AUTOSAR XML (schema 4-0-3)
package /RcCar
  7 x sender receiver interface:
    IfVehicleInfo
      4 x data:
        angle: type=IDT_Angle
        speed: type=IDT_Speed
        pwm_angle: type=IDT_PWM
        pwm_speed: type=IDT_PWM
    IfWinker
      data state: type=IDT_Winker
    IfBuzzer
      data state: type=IDT_Buzzer
    IfLight
      4 x data, all with type=IDT_Light:
        head
        fog
        brake
        back
    IfDriving
      5 x data:
        angle: type=IDT_Angle
        speed: type=IDT_Speed
        steer: type=IDT_Adjust
        gain: type=IDT_Adjust
        brake: type=IDT_Brake
    IfBody
      5 x data, all with type=IDT_Light:
        head
        fog
        hazard
        winker_r
        winker_l
    IfDisplayMode
      6 x data:
        cycle: type=IDT_Cycle
        differ: type=IDT_Switch
        speed: type=IDT_Switch
        angle: type=IDT_Switch
        pwm_angle: type=IDT_PWM
        pwm_speed: type=IDT_PWM
  4 x client server interface:
    IfSteerAngle
      operation OpSetSteerAngle
        arg angle: type=IDT_Angle, direction=IN
    IfDriveSpeed
      operation OpSetDriveSpeed
        arg speed: type=IDT_Speed, direction=IN
    IfDisplayCommand
      operation OpGetDisplayCommand
        arg command: type=IDT_Disp, direction=OUT
    IfPS3Command
      operation OpGetIfPS3Command
        arg command: type=IDT_PS3, direction=OUT
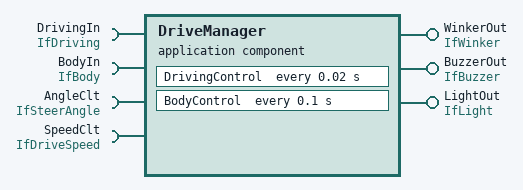
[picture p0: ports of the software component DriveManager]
  application sw component type DriveManager
    provide port WinkerOut: nonqueued-sender-com-spec{data-element=IfWinker/state, init-value=IDT_Winker:0}, provided-interface=IfWinker
    provide port BuzzerOut: nonqueued-sender-com-spec{data-element=IfBuzzer/state, init-value=IDT_Buzzer:0}, provided-interface=IfBuzzer
    provide port LightOut: provided-interface=IfLight
      provided-com-specs:
        data-element=back, init-value=IDT_Light:0
        data-element=IfLight/brake, init-value=IDT_Light:0
        data-element=IfLight/head, init-value=IDT_Light:0
        data-element=IfLight/fog, init-value=IDT_Light:0
    4 x require port:
      DrivingIn: required-interface=IfDriving
        required-com-specs:
          data-element=IfDriving/brake, enable-update=true, handle-never-received=true, init-value=IDT_Brake:1
          data-element=IfDriving/angle, enable-update=true, handle-never-received=true, init-value=IDT_Angle:0
          data-element=gain, enable-update=true, handle-never-received=true, init-value=IDT_Adjust:0
          data-element=IfDriving/speed, enable-update=true, handle-never-received=true, init-value=IDT_Speed:0
          data-element=steer, enable-update=true, handle-never-received=true, init-value=IDT_Adjust:0
      BodyIn: required-interface=IfBody
        required-com-specs:
          data-element=IfBody/fog, enable-update=true, handle-never-received=true, init-value=IDT_Light:0
          data-element=hazard, enable-update=true, handle-never-received=true, init-value=IDT_Light:0
          data-element=IfBody/head, enable-update=true, handle-never-received=true, init-value=IDT_Light:0
          data-element=winker_l, enable-update=true, handle-never-received=true, init-value=IDT_Light:0
          data-element=winker_r, enable-update=true, handle-never-received=true, init-value=IDT_Light:0
      AngleClt: required-interface=IfSteerAngle
      SpeedClt: required-interface=IfDriveSpeed
    behavior IB_DM: handle-termination-and-restart=NO-SUPPORT
      timing event DrivingControl_timingEvent: start-on-event=DrivingControl, period=0.02
      timing event BodyControl_timingEvent: start-on-event=BodyControl, period=0.1
      runnable DrivingControl
        data-receive-point-by-arguments:
          5 x access:
            dataReceivePoint_DrivingControl_DrivingIn_angle: accessed-variable=DrivingIn.angle
            dataReceivePoint_DrivingControl_DrivingIn_speed: accessed-variable=DrivingIn.speed
            dataReceivePoint_DrivingControl_DrivingIn_steer: accessed-variable=DrivingIn.steer
            dataReceivePoint_DrivingControl_DrivingIn_gain: accessed-variable=DrivingIn.gain
            dataReceivePoint_DrivingControl_DrivingIn_brake: accessed-variable=DrivingIn.brake
        sync call serverCallPoint_DrivingControl_AngleClt_OpSetSteerAngle: operation=AngleClt.OpSetSteerAngle, timeout=0.0
        sync call serverCallPoint_DrivingControl_SpeedClt_OpSetDriveSpeed: operation=SpeedClt.OpSetDriveSpeed, timeout=0.0
      runnable BodyControl
        data-receive-point-by-arguments:
          5 x access:
            dataReceivePoint_BodyControl_BodyIn_head: accessed-variable=BodyIn.head
            dataReceivePoint_BodyControl_BodyIn_fog: accessed-variable=BodyIn.fog
            dataReceivePoint_BodyControl_BodyIn_hazard: accessed-variable=BodyIn.hazard
            dataReceivePoint_BodyControl_BodyIn_winker_r: accessed-variable=BodyIn.winker_r
            dataReceivePoint_BodyControl_BodyIn_winker_l: accessed-variable=BodyIn.winker_l
        data-send-points:
          6 x access:
            dataSendPoint_BodyControl_WinkerOut_state: accessed-variable=WinkerOut.state
            dataSendPoint_BodyControl_BuzzerOut_state: accessed-variable=BuzzerOut.state
            dataSendPoint_BodyControl_LightOut_head: accessed-variable=LightOut.head
            dataSendPoint_BodyControl_LightOut_fog: accessed-variable=LightOut.fog
            dataSendPoint_BodyControl_LightOut_brake: accessed-variable=LightOut.brake
            dataSendPoint_BodyControl_LightOut_back: accessed-variable=LightOut.back
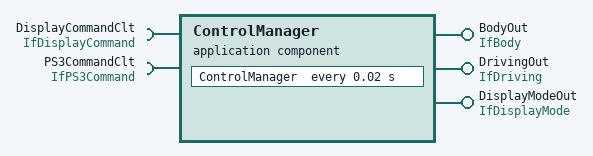
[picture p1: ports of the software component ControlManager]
  application sw component type ControlManager
    provide port BodyOut: provided-interface=IfBody
      provided-com-specs:
        data-element=IfBody/fog, init-value=IDT_Light:0
        data-element=hazard, init-value=IDT_Light:0
        data-element=IfBody/head, init-value=IDT_Light:0
        data-element=winker_l, init-value=IDT_Light:0
        data-element=winker_r, init-value=IDT_Light:0
    provide port DrivingOut: provided-interface=IfDriving
      provided-com-specs:
        data-element=IfDriving/brake, init-value=IDT_Brake:0
        data-element=IfDriving/angle, init-value=IDT_Angle:0
        data-element=gain, init-value=IDT_Adjust:0
        data-element=IfDriving/speed, init-value=IDT_Speed:0
        data-element=steer, init-value=IDT_Adjust:0
    provide port DisplayModeOut: provided-interface=IfDisplayMode
      provided-com-specs:
        data-element=IfDisplayMode/angle, init-value=IDT_Switch:0
        data-element=cycle, init-value=IDT_Cycle:0
        data-element=IfDisplayMode/speed, init-value=IDT_Switch:0
        data-element=differ, init-value=IDT_Switch:0
        data-element=IfDisplayMode/pwm_angle, init-value=IDT_PWM:0
        data-element=IfDisplayMode/pwm_speed, init-value=IDT_PWM:0
    require port DisplayCommandClt: required-interface=IfDisplayCommand
    require port PS3CommandClt: required-interface=IfPS3Command
    behavior IB_CM: handle-termination-and-restart=NO-SUPPORT
      timing event ControlManager_timingEvent: start-on-event=ControlManager, period=0.02
      runnable ControlManager
        data-send-points:
          16 x access:
            dataSendPoint_ControlManager_DrivingOut_angle: accessed-variable=DrivingOut.angle
            dataSendPoint_ControlManager_DrivingOut_speed: accessed-variable=DrivingOut.speed
            dataSendPoint_ControlManager_DrivingOut_steer: accessed-variable=DrivingOut.steer
            dataSendPoint_ControlManager_DrivingOut_gain: accessed-variable=DrivingOut.gain
            dataSendPoint_ControlManager_DrivingOut_brake: accessed-variable=DrivingOut.brake
            dataSendPoint_ControlManager_BodyOut_head: accessed-variable=BodyOut.head
            dataSendPoint_ControlManager_BodyOut_fog: accessed-variable=BodyOut.fog
            dataSendPoint_ControlManager_BodyOut_hazard: accessed-variable=BodyOut.hazard
            dataSendPoint_ControlManager_BodyOut_winker_r: accessed-variable=BodyOut.winker_r
            dataSendPoint_ControlManager_BodyOut_winker_l: accessed-variable=BodyOut.winker_l
            dataSendPoint_ControlManager_DisplayModeOut_cycle: accessed-variable=DisplayModeOut.cycle
            dataSendPoint_ControlManager_DisplayModeOut_differ: accessed-variable=DisplayModeOut.differ
            dataSendPoint_ControlManager_DisplayModeOut_speed: accessed-variable=DisplayModeOut.speed
            dataSendPoint_ControlManager_DisplayModeOut_angle: accessed-variable=DisplayModeOut.angle
            dataSendPoint_ControlManager_DisplayModeOut_pwm_angle: accessed-variable=DisplayModeOut.pwm_angle
            dataSendPoint_ControlManager_DisplayModeOut_pwm_speed: accessed-variable=DisplayModeOut.pwm_speed
        sync call serverCallPoint_ControlManager_DisplayCommandClt_OpGetDisplayCommand: operation=DisplayCommandClt.OpGetDisplayCommand, timeout=0.0
        sync call serverCallPoint_ControlManager_PS3CommandClt_OpGetIfPS3Command: operation=PS3CommandClt.OpGetIfPS3Command, timeout=0.0
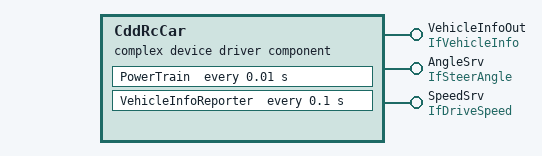
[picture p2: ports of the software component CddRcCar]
  complex device driver sw component type CddRcCar
    provide port VehicleInfoOut: provided-interface=IfVehicleInfo
      provided-com-specs:
        data-element=IfVehicleInfo/angle, init-value=IDT_Angle:0
        data-element=IfVehicleInfo/speed, init-value=IDT_Speed:0
        data-element=IfVehicleInfo/pwm_angle, init-value=IDT_PWM:0
        data-element=IfVehicleInfo/pwm_speed, init-value=IDT_PWM:0
    provide port AngleSrv: provided-interface=IfSteerAngle
    provide port SpeedSrv: provided-interface=IfDriveSpeed
    behavior IB_CR: handle-termination-and-restart=NO-SUPPORT
      timing event PowerTrain_timingEvent: start-on-event=PowerTrain, period=0.01
      timing event VehicleInfoReporter_timingEvent: start-on-event=VehicleInfoReporter, period=0.1
      operation invoked event AngleSrv_OpSetSteerAngle: start-on-event=SetSteerAngle, operation=AngleSrv.OpSetSteerAngle
      operation invoked event SpeedSrv_OpSetDriveSpeed: start-on-event=SetDriveSpeed, operation=SpeedSrv.OpSetDriveSpeed
      4 x runnable:
        PowerTrain
        VehicleInfoReporter
          data-send-points:
            4 x access:
              dataSendPoint_VehicleInfoReporter_VehicleInfoOut_angle: accessed-variable=VehicleInfoOut.angle
              dataSendPoint_VehicleInfoReporter_VehicleInfoOut_speed: accessed-variable=VehicleInfoOut.speed
              dataSendPoint_VehicleInfoReporter_VehicleInfoOut_pwm_angle: accessed-variable=VehicleInfoOut.pwm_angle
              dataSendPoint_VehicleInfoReporter_VehicleInfoOut_pwm_speed: accessed-variable=VehicleInfoOut.pwm_speed
        SetSteerAngle
        SetDriveSpeed
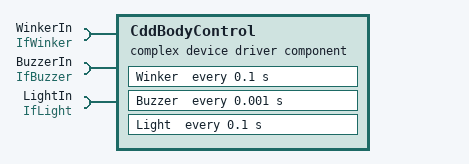
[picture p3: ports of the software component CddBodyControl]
  complex device driver sw component type CddBodyControl
    require port WinkerIn: nonqueued-receiver-com-spec{data-element=IfWinker/state, enable-update=true, handle-never-received=true, init-value=IDT_Winker:0}, required-interface=IfWinker
    require port BuzzerIn: nonqueued-receiver-com-spec{data-element=IfBuzzer/state, enable-update=true, handle-never-received=true, init-value=IDT_Buzzer:0}, required-interface=IfBuzzer
    require port LightIn: required-interface=IfLight
      required-com-specs:
        data-element=back, enable-update=true, handle-never-received=true, init-value=IDT_Light:0
        data-element=IfLight/brake, enable-update=true, handle-never-received=true, init-value=IDT_Light:0
        data-element=IfLight/head, enable-update=true, handle-never-received=true, init-value=IDT_Light:0
        data-element=IfLight/fog, enable-update=true, handle-never-received=true, init-value=IDT_Light:0
    behavior IB_CBC: handle-termination-and-restart=NO-SUPPORT
      timing event Winker_timingEvent: start-on-event=Winker, period=0.1
      timing event Buzzer_timingEvent: start-on-event=Buzzer, period=0.001
      timing event Light_timingEvent: start-on-event=Light, period=0.1
      runnable Winker
        data-receive-point-by-arguments:
          access dataReceivePoint_Winker_WinkerIn_state: accessed-variable=WinkerIn.state
      runnable Buzzer
        data-receive-point-by-arguments:
          access dataReceivePoint_Buzzer_BuzzerIn_state: accessed-variable=BuzzerIn.state
      runnable Light
        data-receive-point-by-arguments:
          4 x access:
            dataReceivePoint_Light_LightIn_head: accessed-variable=LightIn.head
            dataReceivePoint_Light_LightIn_fog: accessed-variable=LightIn.fog
            dataReceivePoint_Light_LightIn_brake: accessed-variable=LightIn.brake
            dataReceivePoint_Light_LightIn_back: accessed-variable=LightIn.back
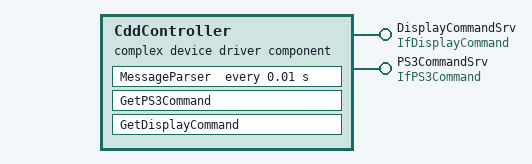
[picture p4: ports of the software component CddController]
  complex device driver sw component type CddController
    provide port DisplayCommandSrv: provided-interface=IfDisplayCommand
    provide port PS3CommandSrv: provided-interface=IfPS3Command
    behavior IB_CC: handle-termination-and-restart=NO-SUPPORT
      exclusive area EaDisplayCommandGotFlg
      exclusive area EaPS3CommandGotFlg
      exclusive area EaUartRx
      timing event MessageParser_timingEvent: start-on-event=MessageParser, period=0.01
      operation invoked event PS3CommandSrv_OpGetIfPS3Command: start-on-event=GetPS3Command, operation=PS3CommandSrv.OpGetIfPS3Command
      operation invoked event DisplayCommandSrv_OpGetDisplayCommand: start-on-event=GetDisplayCommand, operation=DisplayCommandSrv.OpGetDisplayCommand
      runnable MessageParser: can-enter-exclusive-area=EaUartRx
      runnable GetPS3Command: can-enter-exclusive-area=EaPS3CommandGotFlg
      runnable GetDisplayCommand: can-enter-exclusive-area=EaDisplayCommandGotFlg
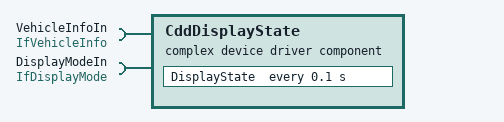
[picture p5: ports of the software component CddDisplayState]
  complex device driver sw component type CddDisplayState
    require port VehicleInfoIn: required-interface=IfVehicleInfo
      required-com-specs:
        data-element=IfVehicleInfo/angle, enable-update=true, handle-never-received=true, init-value=IDT_Angle:0
        data-element=IfVehicleInfo/speed, enable-update=true, handle-never-received=true, init-value=IDT_Speed:0
        data-element=IfVehicleInfo/pwm_angle, enable-update=true, handle-never-received=true, init-value=IDT_PWM:0
        data-element=IfVehicleInfo/pwm_speed, enable-update=true, handle-never-received=true, init-value=IDT_PWM:0
    require port DisplayModeIn: required-interface=IfDisplayMode
      required-com-specs:
        data-element=IfDisplayMode/angle, enable-update=true, handle-never-received=true, init-value=IDT_Switch:0
        data-element=cycle, enable-update=true, handle-never-received=true, init-value=IDT_Cycle:0
        data-element=IfDisplayMode/speed, enable-update=true, handle-never-received=true, init-value=IDT_Switch:0
        data-element=differ, enable-update=true, handle-never-received=true, init-value=IDT_Switch:0
        data-element=IfDisplayMode/pwm_angle, enable-update=true, handle-never-received=true, init-value=IDT_PWM:0
        data-element=IfDisplayMode/pwm_speed, enable-update=true, handle-never-received=true, init-value=IDT_PWM:0
    behavior IB_CDS: handle-termination-and-restart=NO-SUPPORT
      exclusive area EaUartTx
      timing event DisplayState_timingEvent: start-on-event=DisplayState, period=0.1
      runnable DisplayState: can-enter-exclusive-area=EaUartTx
        data-receive-point-by-arguments:
          10 x access:
            dataReceivePoint_DisplayState_VehicleInfoIn_angle: accessed-variable=VehicleInfoIn.angle
            dataReceivePoint_DisplayState_VehicleInfoIn_speed: accessed-variable=VehicleInfoIn.speed
            dataReceivePoint_DisplayState_VehicleInfoIn_pwm_angle: accessed-variable=VehicleInfoIn.pwm_angle
            dataReceivePoint_DisplayState_VehicleInfoIn_pwm_speed: accessed-variable=VehicleInfoIn.pwm_speed
            dataReceivePoint_DisplayState_DisplayModeIn_cycle: accessed-variable=DisplayModeIn.cycle
            dataReceivePoint_DisplayState_DisplayModeIn_differ: accessed-variable=DisplayModeIn.differ
            dataReceivePoint_DisplayState_DisplayModeIn_speed: accessed-variable=DisplayModeIn.speed
            dataReceivePoint_DisplayState_DisplayModeIn_angle: accessed-variable=DisplayModeIn.angle
            dataReceivePoint_DisplayState_DisplayModeIn_pwm_angle: accessed-variable=DisplayModeIn.pwm_angle
            dataReceivePoint_DisplayState_DisplayModeIn_pwm_speed: accessed-variable=DisplayModeIn.pwm_speed
  complex device driver sw component type CddBlinkLed
    behavior IB_CBL: handle-termination-and-restart=NO-SUPPORT
      timing event BlinkLed_timingEvent: start-on-event=BlinkLed, period=0.5
      runnable BlinkLed
  composition sw component type Composition_RcCar
    7 x component:
      DriveManager: type=DriveManager
      CddRcCar: type=CddRcCar
      CddBodyControl: type=CddBodyControl
      ControlManager: type=ControlManager
      CddDisplayState: type=CddDisplayState
      CddController: type=CddController
      CddBlinkLed: type=CddBlinkLed
    connect CddRcCar.AngleSrv -> DriveManager.AngleClt
    connect CddRcCar.SpeedSrv -> DriveManager.SpeedClt
    connect CddRcCar.VehicleInfoOut -> CddDisplayState.VehicleInfoIn
    connect DriveManager.BuzzerOut -> CddBodyControl.BuzzerIn
    connect DriveManager.LightOut -> CddBodyControl.LightIn
    connect DriveManager.WinkerOut -> CddBodyControl.WinkerIn
    connect ControlManager.DrivingOut -> DriveManager.DrivingIn
    connect ControlManager.BodyOut -> DriveManager.BodyIn
    connect ControlManager.DisplayModeOut -> CddDisplayState.DisplayModeIn
    connect CddController.DisplayCommandSrv -> ControlManager.DisplayCommandClt
    connect CddController.PS3CommandSrv -> ControlManager.PS3CommandClt
